# ADuCM4050 register map
Vendor: Analog Devices; Series: ADuCM4050; File version: 1p0
CPU: CM4 r0p1, little endian, MPU, FPU, 3 interrupt priority bits
Registers are 32-bit, read-write, reset 0x0 unless marked. A register's access mark holds for its fields unless they carry their own. Offsets are from the block's base; [hi:lo] are bit positions; {n}, {i} and the like mark numbered series.

## FLCC0_CACHE — Cache Controller
Base 0x40018058
0x00 STAT — Cache Status Register
  [0] ICEN ro — If this bit is set, I-Cache is enabled
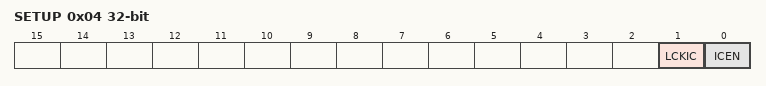
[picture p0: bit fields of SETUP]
0x04 SETUP — Cache Setup Register
  [1] LCKIC range 0x00000000..0x00000001 — If this bit is set, I-Cache contents are locked
  [0] ICEN range 0x00000000..0x00000001 — If this bit set, I-Cache is enabled for AHB accesses
0x08 KEY — Cache Key Register
  [31:0] VALUE wo range 0x00000000..0xFFFFFFFF — Cache Key

## GPIO0 — General-Purpose Input/Output
Base 0x40020000
Same registers: GPIO1 0x40020040, GPIO2 0x40020080, GPIO3 0x400200C0
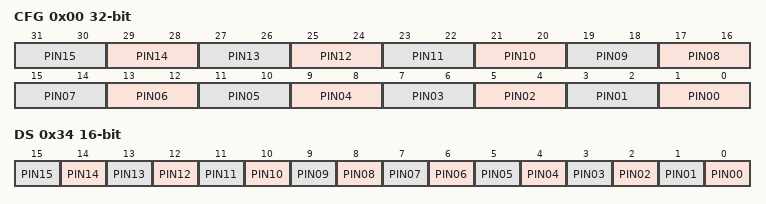
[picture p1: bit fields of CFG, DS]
0x00 CFG — Port Configuration
  [2n+1:2n] PIN{n:02} range 0x00000000..0x00000003 (n=0..15) — Pin {n} configuration bits
0x04 OEN 16-bit — Port Output Enable
  [15:0] VALUE range 0x00000000..0x0000FFFF — Pin Output Drive enable
0x08 PE 16-bit reset 0xC0 — Port Output Pull-up/Pull-down Enable
  [15:0] VALUE range 0x00000000..0x0000FFFF — Pin Pull enable
0x0C IEN 16-bit — Port Input Path Enable
  [15:0] VALUE range 0x00000000..0x0000FFFF — Input path enable
0x10 IN 16-bit — Port Registered Data Input
  [15:0] VALUE ro — Registered data input
0x14 OUT 16-bit — Port Data Output
  [15:0] VALUE range 0x00000000..0x0000FFFF — Data out
0x18 SET 16-bit — Port Data Out Set
  [15:0] VALUE wo range 0x00000000..0x0000FFFF — Set the output HIGH for the pin
0x1C CLR 16-bit — Port Data Out Clear
  [15:0] VALUE wo range 0x00000000..0x0000FFFF — Set the output low for the port pin
0x20 TGL 16-bit — Port Pin Toggle
  [15:0] VALUE wo range 0x00000000..0x0000FFFF — Toggle the output of the port pin
0x24 POL 16-bit — Port Interrupt Polarity
  [15:0] VALUE range 0x00000000..0x0000FFFF — Interrupt polarity
0x28 IENA 16-bit — Port Interrupt A Enable
  [15:0] VALUE range 0x00000000..0x0000FFFF — Interrupt A enable
0x2C IENB 16-bit — Port Interrupt B Enable
  [15:0] VALUE range 0x00000000..0x0000FFFF — Interrupt B enable
0x30 INT 16-bit — Port Interrupt Status
  [15:0] VALUE range 0x00000000..0x0000FFFF — Interrupt Status
0x34 DS 16-bit — Port Drive Strength Select
  [n] PIN{n:02} (n=0..15) — Drive Strength Pin {n:02}
    0=SINGLE_PIN{n:02} (Single Drive Strength); 1=DOUBLE_PIN{n:02} (Double Drive Strength)

## CRC0 — CRC Accelerator
Base 0x40040000
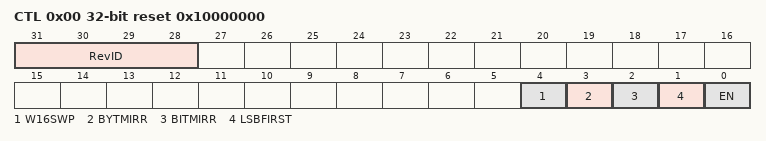
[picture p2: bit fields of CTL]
0x00 CTL reset 0x10000000 — CRC Control
  [31:28] RevID ro — Revision ID
  [4] W16SWP — Word16 Swap
    0=W16SP_DIS (Word16 Swap disabled); 1=W16SP_EN (Word16 Swap enabled)
  [3] BYTMIRR — Byte Mirroring
    0=BYTEMIR_DIS (Byte Mirroring is disabled); 1=BYTEMIR_EN (Byte Mirroring is enabled)
  [2] BITMIRR — Bit Mirroring
    0=BITMIRR_DIS (Bit Mirroring is disabled); 1=BITMIRR_EN (Bit Mirroring is enabled)
  [1] LSBFIRST — LSB First Calculation Order
    0=MSB_FIRST (MSB First CRC calculation is done); 1=LSB_FIRST (LSB First CRC calculation is done)
  [0] EN — CRC Peripheral Enable
    0=CRC_DIS (CRC peripheral is disabled); 1=CRC_EN (CRC peripheral is enabled)
0x04 IPDATA — Input Data Word
  [31:0] VALUE wo range 0x00000000..0xFFFFFFFF — Data Input
0x08 RESULT — CRC Result
  [31:0] VALUE range 0x00000000..0xFFFFFFFF — CRC Residue
0x0C POLY reset 0x4C11DB7 — Programmable CRC Polynomial
  [31:0] VALUE range 0x00000000..0xFFFFFFFF — CRC Reduction Polynomial
{0x10+i} IPBITS[{i}] (i=0..7) 8-bit — Input Data Bits
  [7:0] DATA_BITS wo range 0x00000000..0x000000FF
0x10 IPBYTE 8-bit (alternate view of IPBITS0) — Input Data Byte
  [7:0] DATA_BYTE wo range 0x00000000..0x000000FF

## RNG0 — Random Number Generator
Base 0x40040400
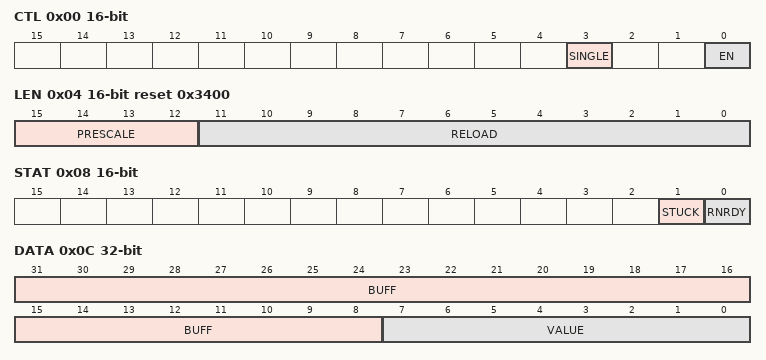
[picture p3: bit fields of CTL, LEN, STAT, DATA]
0x00 CTL 16-bit — RNG Control Register
  [3] SINGLE — Generate a Single Number
    0=WORD (Buffer Word); 1=SINGLE (Single Byte)
  [0] EN — RNG Enable
    0=DISABLE (Disable the RNG); 1=ENABLE (Enable the RNG)
0x04 LEN 16-bit reset 0x3400 — RNG Sample Length Register
  [15:12] PRESCALE range 0x00000000..0x0000000F — Prescaler for the Sample Counter
  [11:0] RELOAD range 0x00000000..0x00000FFF — Reload Value for the Sample Counter
0x08 STAT 16-bit — RNG Status Register
  [1] STUCK range 0x00000000..0x00000001 — Sampled Data Stuck High or Low
  [0] RNRDY — Random Number Ready
0x0C DATA — RNG Data Register
  [31:8] BUFF ro — Buffer for RNG Data
  [7:0] VALUE ro — Value of the CRC Accumulator
0x10 OSCCNT — Oscillator Count
  [27:0] VALUE ro
{0x14+i} OSCDIFF[{i}] (i=0..3) 8-bit — Oscillator Difference
  [7:0] DELTA ro — Oscillator Count Difference
